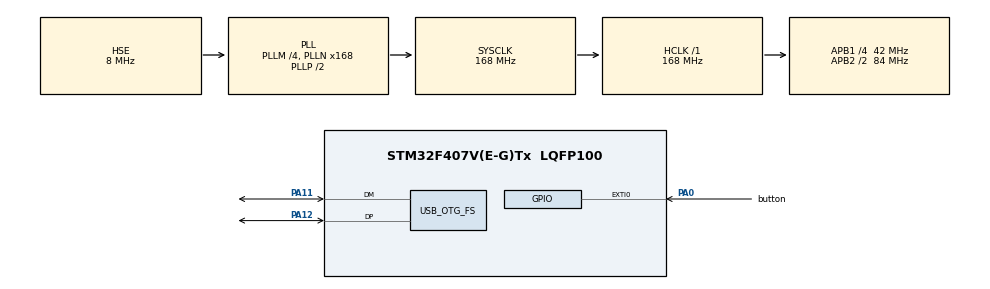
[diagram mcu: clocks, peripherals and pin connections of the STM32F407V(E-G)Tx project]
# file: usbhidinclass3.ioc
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Mcu.Family=STM32F4
Mcu.Name=STM32F407V(E-G)Tx
Mcu.Package=LQFP100
NVIC.EXTI0_IRQn=true\:0\:0\:false\:false\:true\:true\:true
NVIC.OTG_FS_IRQn=true\:0\:0\:false\:false\:true\:false\:true
NVIC.PriorityGroup=NVIC_PRIORITYGROUP_4
PA0-WKUP.GPIO_Label=button
PA0-WKUP.Signal=GPXTI0
PA11.Mode=Device_Only
PA11.Signal=USB_OTG_FS_DM
PA12.Mode=Device_Only
PA12.Signal=USB_OTG_FS_DP
PH0-OSC_IN.Mode=HSE-External-Oscillator
PH0-OSC_IN.Signal=RCC_OSC_IN
PH1-OSC_OUT.Mode=HSE-External-Oscillator
PH1-OSC_OUT.Signal=RCC_OSC_OUT
ProjectManager.HeapSize=0x200
ProjectManager.StackSize=0x400
ProjectManager.TargetToolchain=STM32CubeIDE
RCC.48MHZClocksFreq_Value=48000000
RCC.AHBFreq_Value=168000000
RCC.APB1CLKDivider=RCC_HCLK_DIV4
RCC.APB1Freq_Value=42000000
RCC.APB1TimFreq_Value=84000000
RCC.APB2CLKDivider=RCC_HCLK_DIV2
RCC.APB2Freq_Value=84000000
RCC.APB2TimFreq_Value=168000000
RCC.CortexFreq_Value=168000000
RCC.HCLKFreq_Value=168000000
RCC.HSE_VALUE=8000000
RCC.HSI_VALUE=16000000
RCC.LSE_VALUE=32768
RCC.PLLM=4
RCC.PLLN=168
RCC.PLLQ=7
RCC.SYSCLKFreq_VALUE=168000000
RCC.SYSCLKSource=RCC_SYSCLKSOURCE_PLLCLK
RCC.VCOOutputFreq_Value=336000000
USB_DEVICE.CLASS_NAME_FS=HID
USB_DEVICE.PRODUCT_STRING_HID_FS=STM32keyboard
USB_DEVICE.VirtualMode-HID_FS=Hid
USB_DEVICE.VirtualModeFS=Hid_FS
USB_OTG_FS.VirtualMode=Device_Only
VP_USB_DEVICE_VS_USB_DEVICE_HID_FS.Mode=HID_FS
board=custom

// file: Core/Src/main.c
/* USER CODE BEGIN Header */
/**
  ******************************************************************************
  * @file           : main.c
  * @brief          : Main program body
  ******************************************************************************
  * @attention
  *
  * Copyright (c) 2021 STMicroelectronics.
  * All rights reserved.
  *
  * This software is licensed under terms that can be found in the LICENSE file
  * in the root directory of this software component.
  * If no LICENSE file comes with this software, it is provided AS-IS.
  *
  ******************************************************************************
  */
/* USER CODE END Header */
#include "main.h"
#include "usb_device.h"

/* USER CODE BEGIN Includes */
#include "usbd_hid.h"
/* USER CODE END Includes */

/* USER CODE BEGIN PV */
typedef struct
{
	uint8_t MODIFIER;
	uint8_t RESERVED;
	uint8_t KEYCODE1;
	uint8_t KEYCODE2;
	uint8_t KEYCODE3;
	uint8_t KEYCODE4;
	uint8_t KEYCODE5;
	uint8_t KEYCODE6;
} keyboardData;

keyboardData keyboardhid = {0,0,0,0,0,0,0,0};
extern USBD_HandleTypeDef hUsbDeviceFS;
u_int8_t flag=0;

/* USER CODE END PV */

void SystemClock_Config(void);
static void MX_GPIO_Init(void);

int main(void)
{

  /* MCU Configuration--------------------------------------------------------*/

  /* Reset of all peripherals, Initializes the Flash interface and the Systick. */
  HAL_Init();

  /* Configure the system clock */
  SystemClock_Config();

  /* Initialize all configured peripherals */
  MX_GPIO_Init();
  MX_USB_DEVICE_Init();

  /* Infinite loop */
  while (1)
  {

    /* USER CODE BEGIN 3 */

	  {

		  //keyboardhid.MODIFIER = 0x02;  // left Shift
		  keyboardhid.KEYCODE1 = 0x1e;  // press 'a'
		  keyboardhid.KEYCODE2 = 0x1f;  // press 'b'
		  USBD_HID_SendReport(&hUsbDeviceFS, &keyboardhid, sizeof (keyboardhid));
		  HAL_Delay (50);
		 // keyboardhid.MODIFIER = 0x00;  // shift release
		  keyboardhid.KEYCODE1 = 0x00;  // release key
		  keyboardhid.KEYCODE2 = 0x00;  // release key
		  USBD_HID_SendReport(&hUsbDeviceFS, &keyboardhid, sizeof (keyboardhid));
		  HAL_Delay (1000);

	  }
  }
  /* USER CODE END 3 */
}

void SystemClock_Config(void)
{
  RCC_OscInitTypeDef RCC_OscInitStruct = {0};
  RCC_ClkInitTypeDef RCC_ClkInitStruct = {0};

  /** Configure the main internal regulator output voltage
  */
  __HAL_RCC_PWR_CLK_ENABLE();
  __HAL_PWR_VOLTAGESCALING_CONFIG(PWR_REGULATOR_VOLTAGE_SCALE1);
  /** Initializes the RCC Oscillators according to the specified parameters
  * in the RCC_OscInitTypeDef structure.
  */
  RCC_OscInitStruct.OscillatorType = RCC_OSCILLATORTYPE_HSE;
  RCC_OscInitStruct.HSEState = RCC_HSE_ON;
  RCC_OscInitStruct.PLL.PLLState = RCC_PLL_ON;
  RCC_OscInitStruct.PLL.PLLSource = RCC_PLLSOURCE_HSE;
  RCC_OscInitStruct.PLL.PLLM = 4;
  RCC_OscInitStruct.PLL.PLLN = 168;
  RCC_OscInitStruct.PLL.PLLP = RCC_PLLP_DIV2;
  RCC_OscInitStruct.PLL.PLLQ = 7;
  if (HAL_RCC_OscConfig(&RCC_OscInitStruct) != HAL_OK)
  {
    Error_Handler();
  }
  /** Initializes the CPU, AHB and APB buses clocks
  */
  RCC_ClkInitStruct.ClockType = RCC_CLOCKTYPE_HCLK|RCC_CLOCKTYPE_SYSCLK
                              |RCC_CLOCKTYPE_PCLK1|RCC_CLOCKTYPE_PCLK2;
  RCC_ClkInitStruct.SYSCLKSource = RCC_SYSCLKSOURCE_PLLCLK;
  RCC_ClkInitStruct.AHBCLKDivider = RCC_SYSCLK_DIV1;
  RCC_ClkInitStruct.APB1CLKDivider = RCC_HCLK_DIV4;
  RCC_ClkInitStruct.APB2CLKDivider = RCC_HCLK_DIV2;

  if (HAL_RCC_ClockConfig(&RCC_ClkInitStruct, FLASH_LATENCY_5) != HAL_OK)
  {
    Error_Handler();
  }
}

static void MX_GPIO_Init(void)
{
  GPIO_InitTypeDef GPIO_InitStruct = {0};

  /* GPIO Ports Clock Enable */
  __HAL_RCC_GPIOH_CLK_ENABLE();
  __HAL_RCC_GPIOA_CLK_ENABLE();

  /*Configure GPIO pin : button_Pin */
  GPIO_InitStruct.Pin = button_Pin;
  GPIO_InitStruct.Mode = GPIO_MODE_IT_RISING;
  GPIO_InitStruct.Pull = GPIO_NOPULL;
  HAL_GPIO_Init(button_GPIO_Port, &GPIO_InitStruct);

  /* EXTI interrupt init*/
  HAL_NVIC_SetPriority(EXTI0_IRQn, 0, 0);
  HAL_NVIC_EnableIRQ(EXTI0_IRQn);

}

/* USER CODE BEGIN 4 */
void HAL_GPIO_EXTI_Callback(uint16_t GPIO_Pin)
{
flag=1;
}
/* USER CODE END 4 */

void Error_Handler(void)
{
  __disable_irq();
  while (1)
  {
  }
}
